# PY32F032xx register map
Vendor: Puya; Series: PY32F0; File version: 1.0.0
CPU: CM0+ r0p1, little endian, no MPU, no FPU, 4 interrupt priority bits
Registers are 32-bit, read-write, reset 0x0 unless marked. A register's access mark holds for its fields unless they carry their own. Offsets are from the block's base; [hi:lo] are bit positions; {n}, {i} and the like mark numbered series.

## LPUART
Base 0x40008000
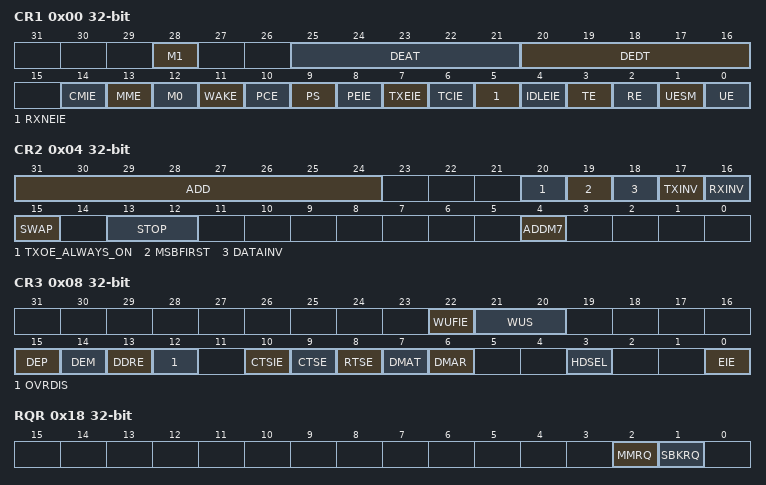
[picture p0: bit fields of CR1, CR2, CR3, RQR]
0x00 CR1
  [28] M1 — The value of {M1,M0} the configurate length
  [25:21] DEAT — The time between the DE (driver enable) signal validity and the start bit
    1=0; 2=1; 4=2; 8=3; 16=4
  [20:16] DEDT — The time between the transmit frame stop bit and the invalid DE (driver enable) signal
    1=0; 2=1; 4=2; 8=3; 16=4
  [14] CMIE — Character match interrupt enabled
  [13] MME — Silent mode enabled
  [12] M0 — Configure the word length in combination with M1
  [11] WAKE — Receive wake-up mode
  [10] PCE — Parity control
  [9] PS — Parity selection
  [8] PEIE — PE interrupt enable
  [7] TXEIE — TXE interrupt enable
  [6] TCIE — End of Transfer interrupt enabled
  [5] RXNEIE — RXNE interrupt enable
  [4] IDLEIE — IDLE interrupt enable
  [3] TE — Transfer enable
  [2] RE — Receive enable
  [1] UESM — LPUART enabled in Stop mode
  [0] UE — LPUART enabled
0x04 CR2
  [31:24] ADD — LPUART address
  [20] TXOE_ALWAYS_ON
  [19] MSBFIRST
  [18] DATAINV — Inverse binary data processing
  [17] TXINV — TX pin active level inverted
  [16] RXINV — The RX pin is active level inverting
  [15] SWAP — TX/RX pin interchangeable
  [13:12] STOP — Stop bit configuration
    1=0; 2=1
  [4] ADDM7 — 7bit/4bit address detection configuration
0x08 CR3
  [22] WUFIE — Low-power wake-up interrupt enable
  [21:20] WUS — Low-power wake-up options
    1=0; 2=1
  [15] DEP — DE polarity selection
  [14] DEM — DE mode enabled
  [13] DDRE — Whether DMA is disabled when receiving an error
  [12] OVRDIS — Overrun is prohibited
  [10] CTSIE — CTS interrupt enable
  [9] CTSE — CTS enabled
  [8] RTSE — RTS enabled
  [7] DMAT — Enable DMA while transmitting
  [6] DMAR — Enable DMA on reception
  [3] HDSEL — Half-duplex selection
  [0] EIE — Error interrupts are enabled
0x0C BRR
  [19:0] BBR — LPUART baud rate
0x18 RQR
  [2] MMRQ — Silent mode request
  [1] SBKRQ — Send an abort request
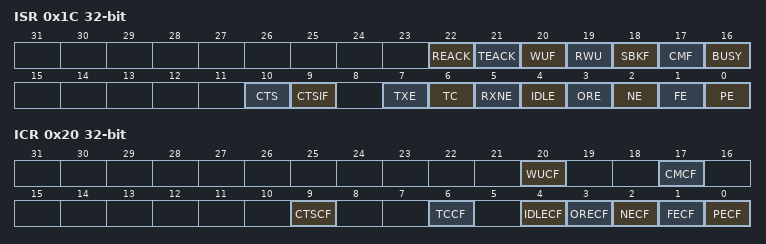
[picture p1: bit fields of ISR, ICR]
0x1C ISR
  [22] REACK ro — Receive the enable acknowledgment flag
  [21] TEACK ro — Transport enable acknowledgement flag
  [20] WUF ro — Wake flag from low-power mode
  [19] RWU ro — Receive Mute mode wake-up flag
  [18] SBKF ro — Send abort flag
  [17] CMF ro — Address match flag
  [16] BUSY ro — Busy flag
  [10] CTS ro — CTS flag
  [9] CTSIF ro — CTS interrupt flag
  [7] TXE ro — TX register empty
  [6] TC ro — Transmission completion flag
  [5] RXNE ro — RX register not empty
  [4] IDLE ro — idle flag
  [3] ORE ro — Overrun error flag
  [2] NE ro — START bit noise flag
  [1] FE ro — Frame error flag
  [0] PE ro — Parity error
0x20 ICR
  [20] WUCF — Low power wake-up flag reset
  [17] CMCF — Address matching flag reset
  [9] CTSCF — CTS flag reset
  [6] TCCF — Transfer completion flag reset
  [4] IDLECF — Clear idle flag
  [3] ORECF — Overrun error flag reset
  [2] NECF — Clear the START bit noise flag
  [1] FECF — Frame error flag reset
  [0] PECF — Check value error flag reset
0x24 RDR
  [8:0] RDR ro — Receive Data Register
0x28 TDR
  [8:0] TDR — Transmit Data Register
0x2C PRESC
  [3:0] PRESCALER — Input clock prescaler register
    1=0; 2=1; 4=2; 8=3
0x34 SAMPMOD
  [0] SAMPMOD — Tolerance sampling mode register

## OPA — Operational amplifier
Base 0x40010300
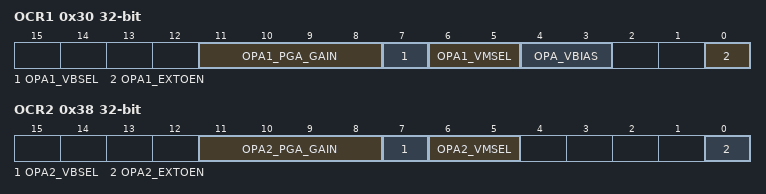
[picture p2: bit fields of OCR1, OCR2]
0x30 OCR1
  [11:8] OPA1_PGA_GAIN, [7] OPA1_VBSEL, [6:5] OPA1_VMSEL, [4:3] OPA_VBIAS, [0] OPA1_EXTOEN
0x34 CR1
  [5] OPA1EN
0x38 OCR2
  [11:8] OPA2_PGA_GAIN, [7] OPA2_VBSEL, [6:5] OPA2_VMSEL, [0] OPA2_EXTOEN
0x3C CR2
  [5] OPA2EN

## PWR — Power control
Base 0x40007000
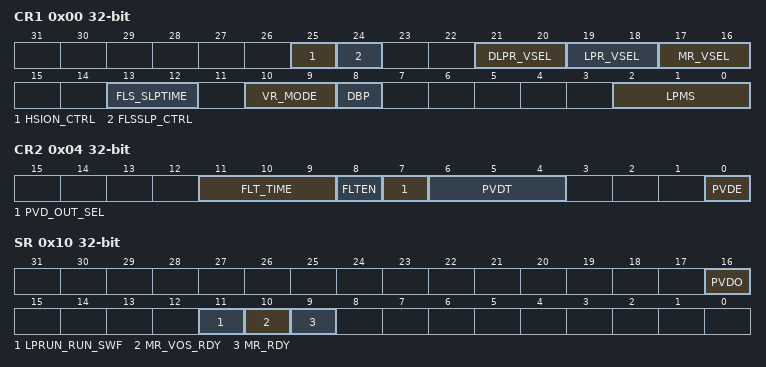
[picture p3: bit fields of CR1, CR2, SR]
0x00 CR1 — Power control register 1
  [25] HSION_CTRL
  [24] FLSSLP_CTRL
  [21:20] DLPR_VSEL
    1=0; 2=1
  [19:18] LPR_VSEL
    1=0; 2=1
  [17:16] MR_VSEL
    1=0; 2=1
  [13:12] FLS_SLPTIME
    1=0; 2=1
  [10:9] VR_MODE
    1=0; 2=1
  [8] DBP
  [2:0] LPMS
0x04 CR2 — Power control register 2
  [11:9] FLT_TIME
    1=0; 2=1; 4=2
  [8] FLTEN
  [7] PVD_OUT_SEL
  [6:4] PVDT
    1=0; 2=1; 4=2
  [0] PVDE
0x10 SR — Power status register
  [16] PVDO ro, [11] LPRUN_RUN_SWF ro, [10] MR_VOS_RDY ro, [9] MR_RDY ro
